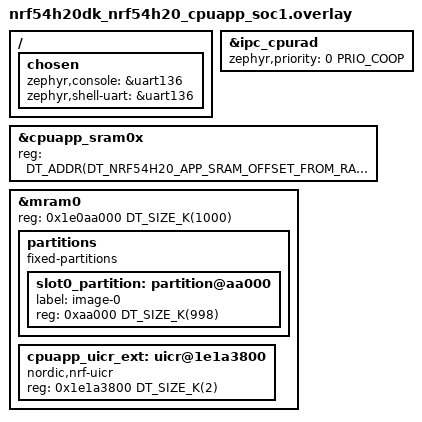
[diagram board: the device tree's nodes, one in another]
/*
 * Copyright (c) 2022 Nordic Semiconductor ASA
 *
 * SPDX-License-Identifier: Apache-2.0
 */

 #include <zephyr/dt-bindings/ipc_service/static_vrings.h>
 #include <common/nordic_nrf_next/nrf54h20_ram0x.dtsi>
 
 /*
  * Chosen dts configs description:
  * - Console and shell-uart connected to the uart-bellboard to get output on server.
  * - SRAM partition placed in ram0x due to its big size and speed.
  * - - Current flash layout does not allow the application domain to use both mram10 and mram11 in one continuous block. mram11 is selected due to its available size.
  * - flash_controller2 is defined to allow using RAM as a FLASH simulator - it is required to store Zephyr's settings in RAM.
  */
 
 / {
     chosen {
         zephyr,console = &uart136;
         zephyr,shell-uart = &uart136;
     };
 };
 
 &ipc_cpurad {
     zephyr,priority = <0 PRIO_COOP>;
 };
 
 ipc0: &ipc_cpurad { };
 
 
 &cpuapp_sram0x {
     reg = <DT_ADDR(DT_NRF54H20_APP_SRAM_OFFSET_FROM_RAM0X_S) DT_SIZE_K(350)>;
 };
 
 /delete-node/ &slot0_partition;
 /delete-node/ &cpuapp_uicr_ext;
 
 &mram0 {
     reg = <0x1e0aa000 DT_SIZE_K(1000)>;
     partitions {
         compatible = "fixed-partitions";
         #address-cells = < 0x1 >;
         #size-cells = < 0x1 >;
         slot0_partition: partition@aa000 {
             label = "image-0";
             reg = < 0xaa000 DT_SIZE_K(998) >;
         };
     };
     cpuapp_uicr_ext: uicr@1e1a3800 {
         compatible = "nordic,nrf-uicr";
         reg = <0x1e1a3800 DT_SIZE_K(2)>;
     };
 };
